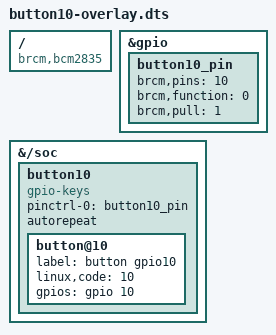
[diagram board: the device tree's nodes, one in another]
/dts-v1/;
/plugin/;

/ {
    compatible = "brcm,bcm2835", "brcm,bcm2708", "brcm,bcm2709";

    fragment@0 {
        target = <&gpio>;
        __overlay__ {
            button10_pin: button10_pin {
                brcm,pins = <10>;     /* gpio10 */
                brcm,function = <0>; /* input */
                brcm,pull = <1>;     /* pull-down */
            };
        };
    };

    fragment@1 {
    target-path = "/soc";
        __overlay__ {
            button10: button10 {
                compatible = "gpio-keys";
                #address-cells = <1>;
                #size-cells = <0>;
                pinctrl-names = "default";
                pinctrl-0 = <&button10_pin>;
                status = "okay";
                autorepeat;

                button@10 {
                    label = "button gpio10";
                    linux,code = <10>;
                    gpios = <&gpio 10 0>;
                };
            };
        };
    };
};

